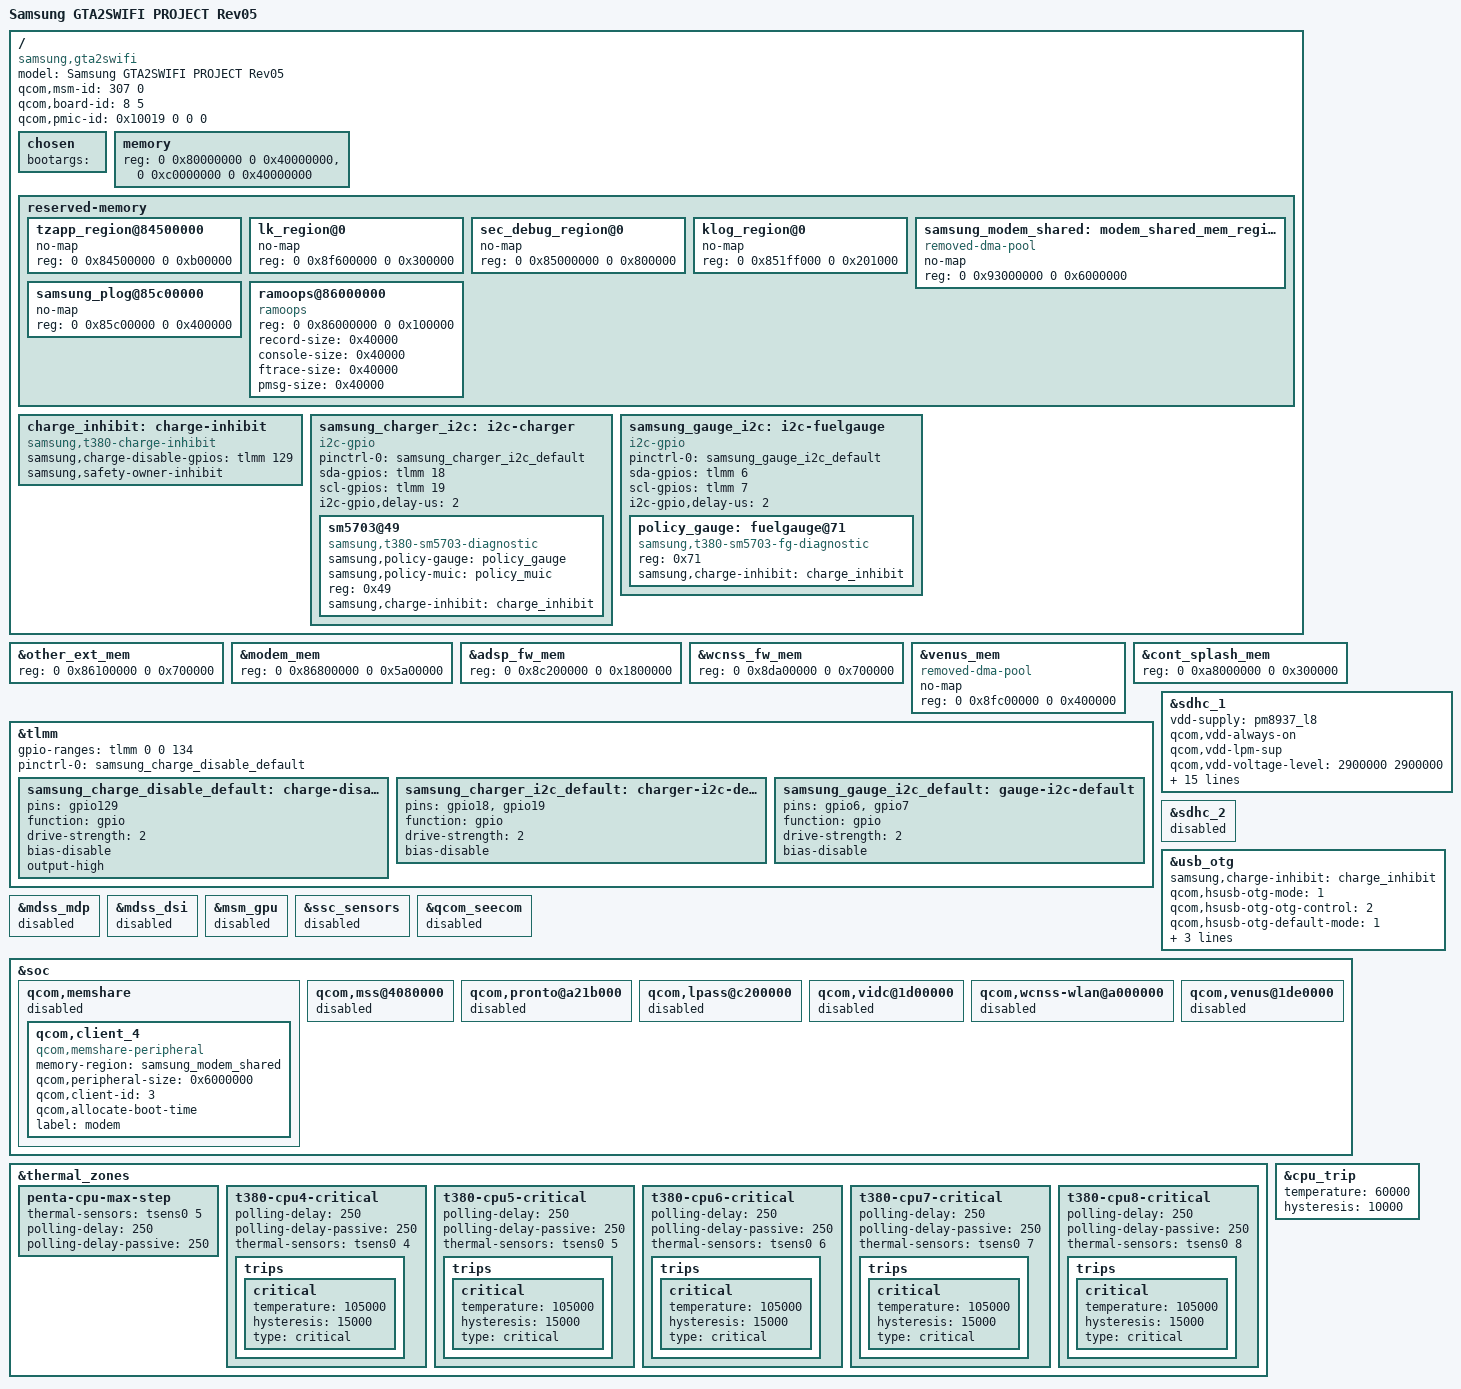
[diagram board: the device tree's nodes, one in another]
// SPDX-License-Identifier: GPL-2.0-only
/dts-v1/;

/* SoC support from 704f6f08, board wiring from captured live Rev05 DT. */
#include "../vendor-legacy/qcom/msm8917.dtsi"
#include <dt-bindings/gpio/gpio.h>

/ {
    model = "Samsung GTA2SWIFI PROJECT Rev05";
    compatible = "samsung,gta2swifi", "qcom,apq8017-mtp", "qcom,apq8017", "qcom,mtp";
    qcom,msm-id = <307 0>;
    qcom,board-id = <8 5>;
    qcom,pmic-id = <0x10019 0 0 0>;

    chosen {
        /* Bootloader adds board args; do not inherit donor kpti=0. */
        bootargs = "";
    };
    memory {
        reg = <0 0x80000000 0 0x40000000>, <0 0xc0000000 0 0x40000000>;
    };
    /* The diagnostic initramfs must not auto-discover Android partitions. */
    /delete-node/ firmware;

    reserved-memory {
        tzapp_region@84500000 { no-map; reg = <0 0x84500000 0 0xb00000>; };
        /* Samsung firmware looks up these exact paths before Linux starts.
         * It removes lk/sec_debug or klog according to boot/debug flags. */
        lk_region@0 { no-map; reg = <0 0x8f600000 0 0x300000>; };
        sec_debug_region@0 { no-map; reg = <0 0x85000000 0 0x800000>; };
        klog_region@0 { no-map; reg = <0 0x851ff000 0 0x201000>; };
        samsung_modem_shared: modem_shared_mem_region@0x93000000 {
            compatible = "removed-dma-pool";
            no-map;
            reg = <0 0x93000000 0 0x6000000>;
        };
        samsung_plog@85c00000 { no-map; reg = <0 0x85c00000 0 0x400000>; };
        ramoops@86000000 {
            compatible = "ramoops";
            reg = <0 0x86000000 0 0x100000>;
            record-size = <0x40000>;
            console-size = <0x40000>;
            ftrace-size = <0x40000>;
            pmsg-size = <0x40000>;
        };
    };

    charge_inhibit: charge-inhibit {
        compatible = "samsung,t380-charge-inhibit";
        samsung,charge-disable-gpios = <&tlmm 129 GPIO_ACTIVE_HIGH>;
        samsung,safety-owner-inhibit;
    };

    samsung_charger_i2c: i2c-charger {
        compatible = "i2c-gpio";
        pinctrl-names = "default";
        pinctrl-0 = <&samsung_charger_i2c_default>;
        #address-cells = <1>;
        #size-cells = <0>;
        sda-gpios = <&tlmm 18 GPIO_ACTIVE_HIGH>;
        scl-gpios = <&tlmm 19 GPIO_ACTIVE_HIGH>;
        i2c-gpio,delay-us = <2>;
        sm5703@49 {
            compatible = "samsung,t380-sm5703-diagnostic";
        samsung,policy-gauge = <&policy_gauge>;
        samsung,policy-muic = <&policy_muic>;
            reg = <0x49>;
            samsung,charge-inhibit = <&charge_inhibit>;
        };
    };
    samsung_gauge_i2c: i2c-fuelgauge {
        compatible = "i2c-gpio";
        pinctrl-names = "default";
        pinctrl-0 = <&samsung_gauge_i2c_default>;
        #address-cells = <1>;
        #size-cells = <0>;
        sda-gpios = <&tlmm 6 GPIO_ACTIVE_HIGH>;
        scl-gpios = <&tlmm 7 GPIO_ACTIVE_HIGH>;
        i2c-gpio,delay-us = <2>;
        policy_gauge: fuelgauge@71 {
            compatible = "samsung,t380-sm5703-fg-diagnostic";
            reg = <0x71>;
            samsung,charge-inhibit = <&charge_inhibit>;
        };
    };
};

/* Preserve fixed Samsung firmware reservations, including APQ modem memory. */
&other_ext_mem { reg = <0 0x86100000 0 0x700000>; };
&modem_mem { reg = <0 0x86800000 0 0x5a00000>; };
&adsp_fw_mem { reg = <0 0x8c200000 0 0x1800000>; };
&wcnss_fw_mem { reg = <0 0x8da00000 0 0x700000>; };
&venus_mem {
    /delete-property/ reusable;
    /delete-property/ alloc-ranges;
    /delete-property/ alignment;
    /delete-property/ size;
    compatible = "removed-dma-pool";
    no-map;
    reg = <0 0x8fc00000 0 0x400000>;
};
&cont_splash_mem { reg = <0 0xa8000000 0 0x300000>; };

&tlmm {
    /* GPIO hogs are scanned inside gpiochip_add_data(), before the driver's
     * fallback range is installed. Supply the range before that scan. */
    gpio-ranges = <&tlmm 0 0 134>;
    /* Provider self pinctrl hogs run before msm_gpio_init(). GPIO requests
     * alone do not select mux function in this donor pinctrl implementation. */
    pinctrl-names = "default";
    pinctrl-0 = <&samsung_charge_disable_default>;
    samsung_charge_disable_default: charge-disable-default {
        pins = "gpio129";
        function = "gpio";
        drive-strength = <2>;
        bias-disable;
        output-high;
    };
    samsung_charger_i2c_default: charger-i2c-default {
        pins = "gpio18", "gpio19";
        function = "gpio";
        drive-strength = <2>;
        bias-disable;
    };
    samsung_gauge_i2c_default: gauge-i2c-default {
        pins = "gpio6", "gpio7";
        function = "gpio";
        drive-strength = <2>;
        bias-disable;
    };
    /* GPIO129 is requested HIGH by the early exclusive safety owner.
     * Provider output-high pinctrl above remains before GPIO registration. */
};

&sdhc_1 {
    vdd-supply = <&pm8937_l8>;
    qcom,vdd-always-on;
    qcom,vdd-lpm-sup;
    qcom,vdd-voltage-level = <2900000 2900000>;
    qcom,vdd-current-level = <200 570000>;
    vdd-io-supply = <&pm8937_l5>;
    qcom,vdd-io-always-on;
    qcom,vdd-io-lpm-sup;
    qcom,vdd-io-voltage-level = <1800000 1800000>;
    qcom,vdd-io-current-level = <200 325000>;
    pinctrl-names = "active", "sleep";
    pinctrl-0 = <&sdc1_clk_on &sdc1_cmd_on &sdc1_data_on &sdc1_rclk_on>;
    pinctrl-1 = <&sdc1_clk_off &sdc1_cmd_off &sdc1_data_off &sdc1_rclk_off>;
    qcom,clk-rates = <400000 20000000 25000000 50000000 100000000 192000000 384000000>;
    qcom,nonremovable;
    qcom,bus-speed-mode = "HS400_1p8v", "HS200_1p8v", "DDR_1p8v";
    status = "okay";
};
&sdhc_2 { status = "disabled"; };

&usb_otg {
    /delete-property/ vbus_otg-supply;
    /delete-property/ qcom,enable-sdp-typec-current-limit;
    samsung,charge-inhibit = <&charge_inhibit>;
    qcom,hsusb-otg-mode = <1>; /* USB_PERIPHERAL; never source VBUS */
    qcom,hsusb-otg-otg-control = <2>; /* PMIC/real-VBUS notification */
    qcom,hsusb-otg-default-mode = <1>;
    samsung,vbus-extcon = <&policy_muic>;
    qcom,hsusb-otg-phy-init-seq = <0x5d 0x81 0x2b 0x82 0xffffffff>;
    status = "okay";
};

/* No panel selection or boot-time peripheral firmware loading in this image. */
&mdss_mdp { status = "disabled"; };
&mdss_dsi { status = "disabled"; };
&msm_gpu { status = "disabled"; };
&ssc_sensors { status = "disabled"; };
&qcom_seecom { status = "disabled"; };
&soc {
    /* Firmware removes this client with its reservation when modem shared
     * memory is disabled, or updates both sizes before kernel handoff. */
    qcom,memshare {
        /* Exact nodes remain available to firmware fixups without starting
         * modem allocation/QMI services in the diagnostic kernel. */
        status = "disabled";
        qcom,client_4 {
            compatible = "qcom,memshare-peripheral";
            memory-region = <&samsung_modem_shared>;
            qcom,peripheral-size = <0x6000000>;
            qcom,client-id = <3>;
            qcom,allocate-boot-time;
            label = "modem";
        };
    };
    qcom,mss@4080000 { status = "disabled"; };
    qcom,pronto@a21b000 { status = "disabled"; };
    qcom,lpass@c200000 { status = "disabled"; };
    qcom,vidc@1d00000 { status = "disabled"; };
    qcom,wcnss-wlan@a000000 { status = "disabled"; };
    qcom,venus@1de0000 { status = "disabled"; };
};

/* Samsung throttled at 60 C and reset at 105 C. Diagnostic userspace has
 * no Android thermal daemon, so use automatic kernel mitigation. */
&thermal_zones {
    penta-cpu-max-step {
        thermal-sensors = <&tsens0 5>;
        polling-delay = <250>;
        polling-delay-passive = <250>;
    };
    t380-cpu4-critical {
        polling-delay = <250>;
        polling-delay-passive = <250>;
        thermal-sensors = <&tsens0 4>;
        trips { critical { temperature = <105000>; hysteresis = <15000>; type = "critical"; }; };
    };
    t380-cpu5-critical {
        polling-delay = <250>;
        polling-delay-passive = <250>;
        thermal-sensors = <&tsens0 5>;
        trips { critical { temperature = <105000>; hysteresis = <15000>; type = "critical"; }; };
    };
    t380-cpu6-critical {
        polling-delay = <250>;
        polling-delay-passive = <250>;
        thermal-sensors = <&tsens0 6>;
        trips { critical { temperature = <105000>; hysteresis = <15000>; type = "critical"; }; };
    };
    t380-cpu7-critical {
        polling-delay = <250>;
        polling-delay-passive = <250>;
        thermal-sensors = <&tsens0 7>;
        trips { critical { temperature = <105000>; hysteresis = <15000>; type = "critical"; }; };
    };
    t380-cpu8-critical {
        polling-delay = <250>;
        polling-delay-passive = <250>;
        thermal-sensors = <&tsens0 8>;
        trips { critical { temperature = <105000>; hysteresis = <15000>; type = "critical"; }; };
    };
};
&cpu_trip { temperature = <60000>; hysteresis = <10000>; };

#include "gta2swifi-display.dtsi"

#include "gta2swifi-touch.dtsi"

#include "gta2swifi-thermal.dtsi"

#include "gta2swifi-gpu.dtsi"

#include "gta2swifi-wifi.dtsi"

#include "gta2swifi-battery-thermal.dtsi"

#include "gta2swifi-muic-observation.dtsi"
